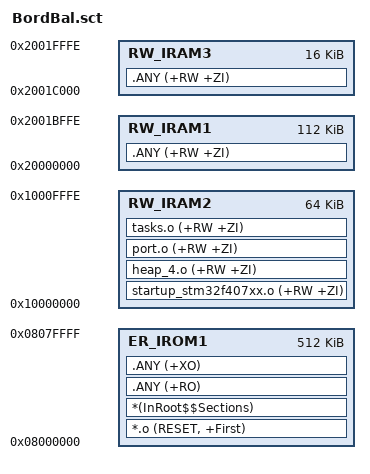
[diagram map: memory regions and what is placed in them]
; *************************************************************
; *** Scatter-Loading Description File generated by uVision ***
; *************************************************************

LR_IROM1 0x08000000 0x00080000  {    ; load region size_region
  ER_IROM1 0x08000000 0x00080000  {  ; load address = execution address
   *.o (RESET, +First)
   *(InRoot$$Sections)
   .ANY (+RO)
   .ANY (+XO)
  }
  RW_IRAM2 0x10000000 0x0000FFFF  {
	startup_stm32f407xx.o (+RW +ZI)
	heap_4.o (+RW +ZI)
	;queue.o (+RW +ZI)
	port.o (+RW +ZI)
	tasks.o (+RW +ZI)
	;timers.o (+RW +ZI)
  }
  RW_IRAM3 0x2001C000 0x00003FFF  {
	.ANY (+RW +ZI)
  }
  RW_IRAM1 0x20000000 0x0001BFFF  {  ; RW data
    .ANY (+RW +ZI)
  }
}

